# ATtiny43U device description
Architecture: AVR8; Family: tinyAVR
Programming and debug interfaces: ISP, HVPP, debugWIRE
Registers are 8-bit, access not given, no defined reset value unless marked. A register's access mark holds for its fields unless they carry their own. Offsets are from the block's base; lines under a group give offsets from that group; [hi:lo] are bit positions; {n}, {i} and the like mark numbered series; 'fields as' and 'values as' point back to an identical list; <NAME> marks a mode.

## Ordering variants
standard: 0.7 to 5.5 V

## Memory
prog space: start 0x0000 size 0x1000, little endian
  0x0000 FLASH size 0x1000 flash, rw, executable, page 0x40
signatures space: start 0 size 3, little endian
  0 SIGNATURES size 3 signatures, ro
fuses space: start 0 size 0x0003, little endian
  0 FUSES size 0x0003 fuses, rw
lockbits space: start 0 size 0x0001, little endian
  0 LOCKBITS size 0x0001 lockbits, rw
data space: start 0x0000 size 0x0160, little endian
  0x0000 REGISTERS size 0x0020 regs
  0x0020 MAPPED_IO size 0x0040 io
  0x0060 IRAM size 0x0100 ram
eeprom space: start 0x0000 size 0x0040, little endian
  0x0000 EEPROM size 0x0040 eeprom, rw, page 0x04
io space: start 0x00 size 0x40, little endian
osccal space: start 0 size 1, little endian
  0 OSCCAL size 1 osccal, ro

## Peripheral instances (address, pins/pin function, parameters)
PORTA at 0x00 — I/O Port
PORTB at 0x00 — I/O Port
USI at 0x00 — Universal Serial Interface
WDT at 0x00 — Watchdog Timer
TC0 at 0x00 — Timer/Counter, 8-bit
TC1 at 0x00 — Timer/Counter, 8-bit
BOOT_LOAD at 0x00 — Bootloader
CPU at 0x00 — CPU Registers
EXINT at 0x00 — External Interrupts
AC at 0x00 — Analog Comparator
ADC at 0x00 — Analog-to-Digital Converter
EEPROM at 0x00
FUSE at 0 in fuses — Fuses
LOCKBIT at 0 in lockbits — Lockbits

## Interrupts
0 RESET — External Pin, Power-on Reset, Brown-out Reset,Watchdog Reset
1 INT0 — External Interrupt Request 0
2 PCINT0 — Pin Change Interrupt Request 0
3 PCINT1 — Pin Change Interrupt Request 1
4 WDT — Watchdog Time-out
5 TIM1_COMPA — Timer/Counter1 Compare Match A
6 TIM1_COMPB — Timer/Counter1 Compare Match B
7 TIM1_OVF — Timer/Counter1 Overflow
8 TIM0_COMPA — Timer/Counter0 Compare Match A
9 TIM0_COMPB — Timer/Counter0 Compare Match B
10 TIM0_OVF — Timer/Counter0 Overflow
11 ANA_COMP — Analog Comparator
12 ADC — ADC Conversion Complete
13 EE_RDY — EEPROM Ready
14 USI_START
15 USI_OVF — USI Overflow

## Properties
SIGNATURES: JTAGID=0x920C, SIGNATURE0=0x1e, SIGNATURE1=0x92, SIGNATURE2=0x0c
OCD: OCD_REVISION=1, OCD_DATAREG=0x27, PROGBASE=0x0000

## LOCKBIT — Lockbits
Instances: LOCKBIT 0 in lockbits
0x00 LOCKBIT
  [1:0] LB — Memory Lock
    0=PROG_VER_DISABLED (Further programming and verification disabled); 2=PROG_DISABLED (Further programming disabled); 3=NO_LOCK (No memory lock features enabled)

## PORTA — I/O Port
Instances: PORTA 0x00
0x39 PINA — Port A Input Pins
0x3A DDRA — Port A Data Direction Register
0x3B PORTA — Port A Data Register

## PORTB — I/O Port
Instances: PORTB 0x00
0x36 PINB — Port B Input Pins
0x37 DDRB — Port B Data Direction Register
0x38 PORTB — Port B Data Register

## USI — Universal Serial Interface
Instances: USI 0x00
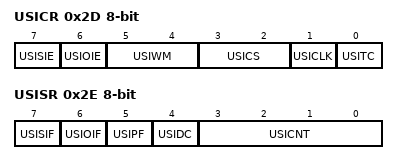
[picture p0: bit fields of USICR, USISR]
0x2D USICR — USI Control Register
  [7] USISIE — Start Condition Interrupt Enable
  [6] USIOIE — Counter Overflow Interrupt Enable
  [5:4] USIWM — USI Wire Mode Bits
    0=Normal Operation; 1=Three-Wire Mode; 2=Two-Wire Mode; 3=Two-Wire Mode Held Low
  [3:2] USICS — USI Clock Source Select Bits
  [1] USICLK — Clock Strobe
  [0] USITC — Toggle Clock Port Pin
0x2E USISR — USI Status Register
  [7] USISIF — Start Condition Interrupt Flag
  [6] USIOIF — Counter Overflow Interrupt Flag
  [5] USIPF — Stop Condition Flag
  [4] USIDC — Data Output Collision
  [3:0] USICNT — USI Counter Value Bits
0x2F USIDR — USI Data Register
0x30 USIBR — USI Buffer Register

## WDT — Watchdog Timer
Instances: WDT 0x00
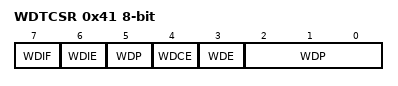
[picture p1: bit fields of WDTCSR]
0x41 WDTCSR — Watchdog Timer Control Register
  [7] WDIF — Watchdog Timeout Interrupt Flag
  [6] WDIE — Watchdog Timeout Interrupt Enable
  [4] WDCE — Watchdog Change Enable
  [3] WDE — Watch Dog Enable
  [5,2:0] WDP — Watchdog Timer Prescaler Bits
    0=Oscillator Cycles 2K; 1=Oscillator Cycles 4K; 2=Oscillator Cycles 8K; 3=Oscillator Cycles 16K; 4=Oscillator Cycles 32K; 5=Oscillator Cycles 64K; 6=Oscillator Cycles 128K; 7=Oscillator Cycles 256K; 8=Oscillator Cycles 512K; 9=Oscillator Cycles 1024K
